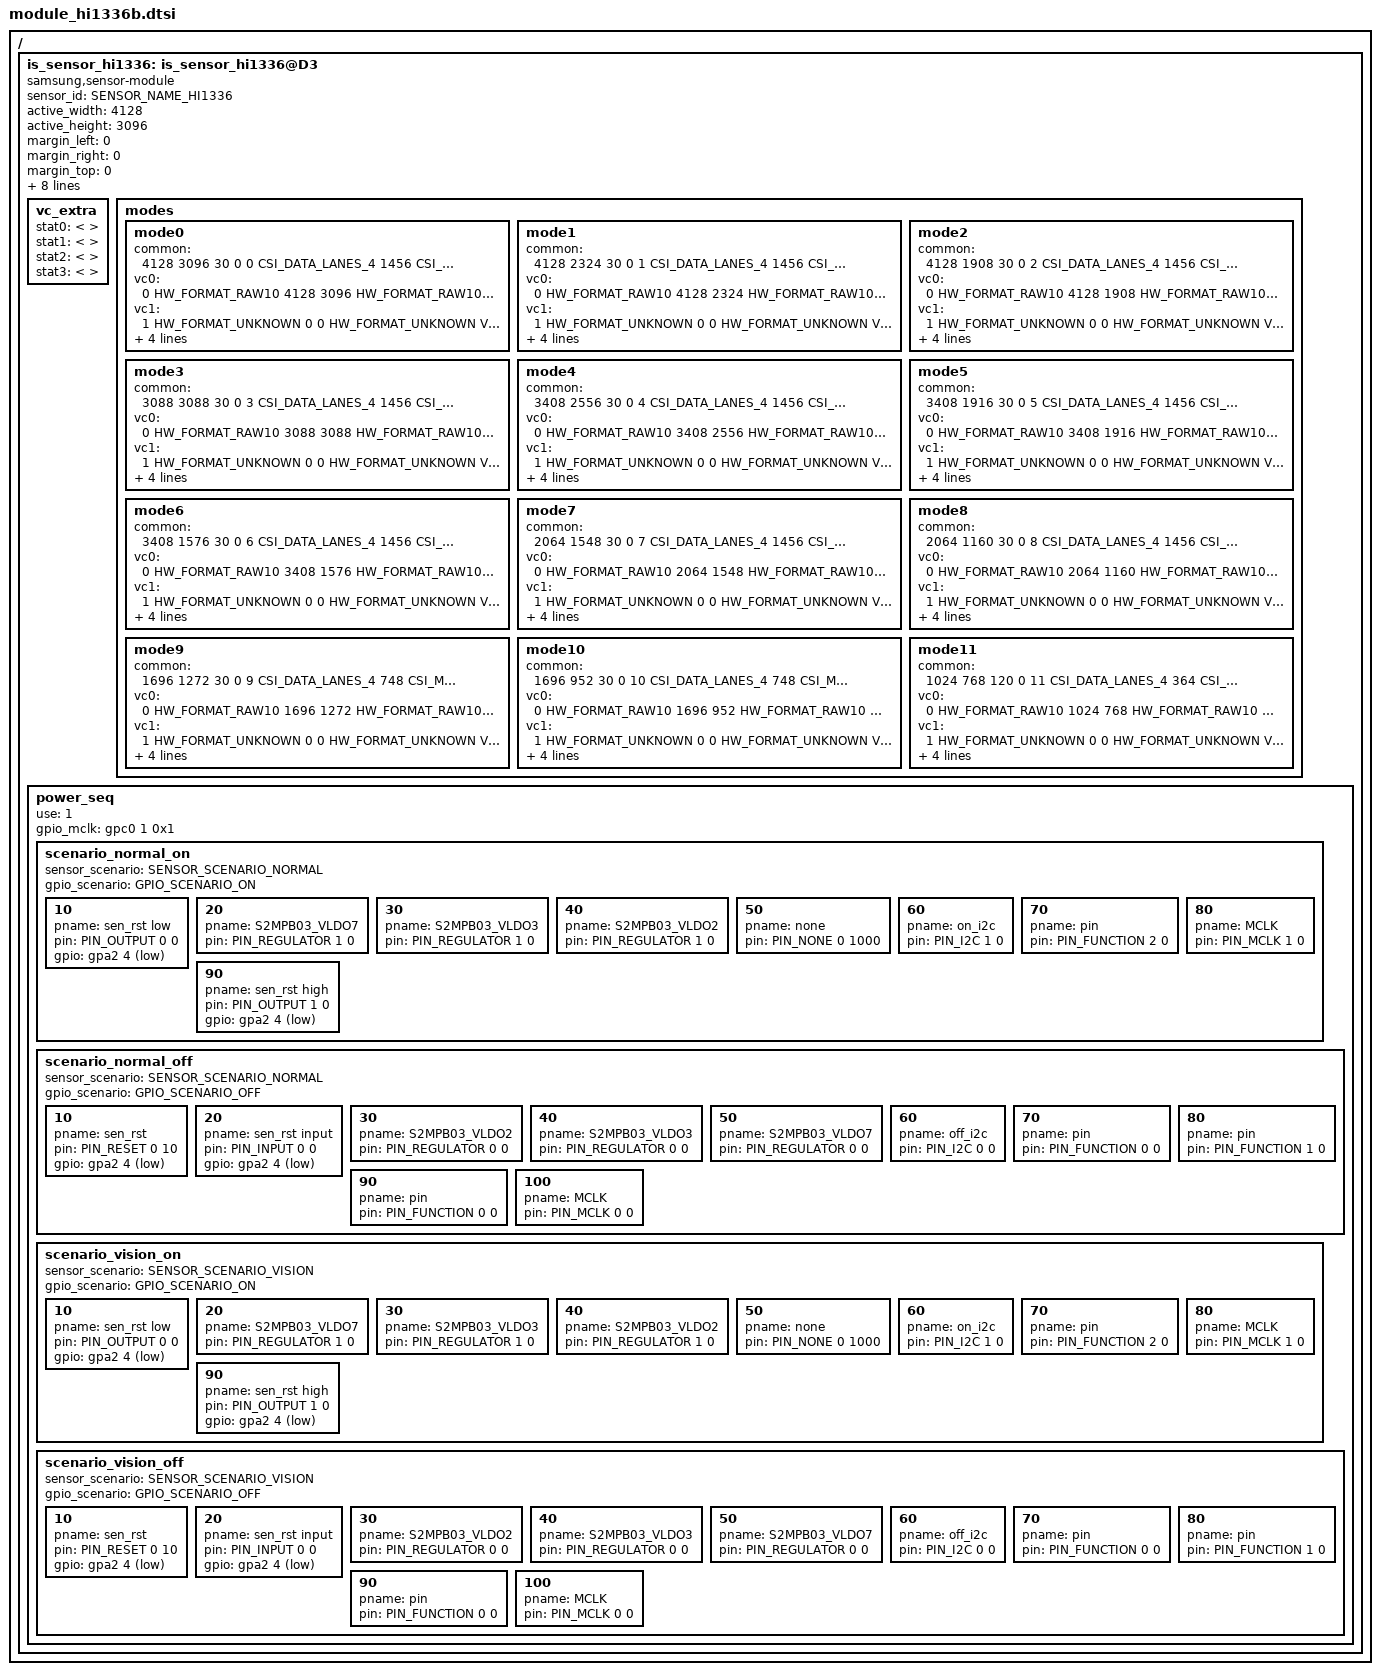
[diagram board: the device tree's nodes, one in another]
/*
 * SAMSUNG EXYNOSxxxx board camera device tree source
 *
 * Copyright (c) 2019 Samsung Electronics Co., Ltd.
 *		http://www.samsung.com
 *
 * This program is free software; you can redistribute it and/or modify
 * it under the terms of the GNU General Public License version 2 as
 * published by the Free Software Foundation.
 */

#include <dt-bindings/camera/exynos_is_dt.h>

/ {
	fragment@camera {
		target-path = "/";
		__overlay__ {
			is_sensor_hi1336: is_sensor_hi1336@D3 {
				compatible = "samsung,sensor-module";

				/* common */
				sensor_id = <SENSOR_NAME_HI1336>;
				active_width = <4128>;
				active_height = <3096>;
				margin_left = <0>;
				margin_right = <0>;
				margin_top = <0>;
				margin_bottom = <0>;
				max_framerate = <120>;
				bitwidth = <10>;
				use_retention_mode = <SENSOR_RETENTION_UNSUPPORTED>;
				sensor_maker = "HYNIX";
				sensor_name = "HI1336";
				setfile_name = "setfile_hi1336.bin";

				status = "okay";

				vc_extra {
					/* ex) statX = <stat_type, sensor_mode, max_width, max_height, max_element> */
					stat0 = </* not avaliable */>;	/* VC_BUF_DATA_TYPE_SENSOR_STAT1 */
					stat1 = </* not avaliable */>;	/* VC_BUF_DATA_TYPE_GENERAL_STAT1 */
					stat2 = </* not avaliable */>;	/* VC_BUF_DATA_TYPE_SENSOR_STAT2 */
					stat3 = </* not avaliable */>;	/* VC_BUF_DATA_TYPE_GENERAL_STAT2 */
				};

				/*
				 * [Mode Information]
				 *
				 *  - Global setting
				 *
				 *
				 *  - Default Mode setting For HI1336B
				 *  [ 0 ] 4128 x 3096(4:3)      @30,  MIPI lane: 4, MIPI data rate(Mbps/lane):  1456, Mclk(Mhz): 26
				 *  [ 1 ] 4128 x 2324(16:9)     @30,  MIPI lane: 4, MIPI data rate(Mbps/lane):  1456, Mclk(Mhz): 26
				 *  [ 2 ] 4128 x 1908(19.5:9)   @30,  MIPI lane: 4, MIPI data rate(Mbps/lane):  1456, Mclk(Mhz): 26
				 *  [ 3 ] 3088 x 3088(1:1)      @30,  MIPI lane: 4, MIPI data rate(Mbps/lane):  1456, Mclk(Mhz): 26
				 *      - Sensor Crop Mode (68') setting For HI1336B
				 *  [ 4 ] 3408 x 2556(4:3)      @30,  MIPI lane: 4, MIPI data rate(Mbps/lane):  1456, Mclk(Mhz): 26
				 *  [ 5 ] 3408 x 1916(16:9)     @30,  MIPI lane: 4, MIPI data rate(Mbps/lane):  1456, Mclk(Mhz): 26
				 *  [ 6 ] 3408 x 1576(19.5:9)   @30,  MIPI lane: 4, MIPI data rate(Mbps/lane):  1456, Mclk(Mhz): 26
				 *  [ 7 ] 2064 x 1548(4:3)      @30,  MIPI lane: 4, MIPI data rate(Mbps/lane):  1456, Mclk(Mhz): 26
				 *  [ 8 ] 2064 x 1160(16:9)     @30,  MIPI lane: 4, MIPI data rate(Mbps/lane):  1456, Mclk(Mhz): 26
				 *  [ 9 ] 1696 x 1272(4:3)      @30,  MIPI lane: 4, MIPI data rate(Mbps/lane):  747.5, Mclk(Mhz): 26
				 *  [ 10 ] 1696 x 952 (16:9)     @30,  MIPI lane: 4, MIPI data rate(Mbps/lane):  747.5, Mclk(Mhz): 26
				 *       - FAST AE (4 binning) setting For HI1336B
				 *  [ 11 ] 1024 x 768(4:3)       @120, MIPI lane: 4, MIPI data rate(Mbps/lane):   364, Mclk(Mhz): 26
				 *
				 *
				 *  - Fsync setting
				 *  [ 0 ] Normal
				 *  [ 1 ] Slave
				 *  [ 2 ] Master full
				 *  [ 3 ] Master 2-binnig
				 *  [ 4 ] Master 4-binning
				 *
				 */

				/* sensor modes */
				modes {
						/* common = <width, height, fps, settle, mode, lane, speed, interleave, lrte, pd_mode> */
						/* vcX = <map, hwformat, width, height, hwformat, type, width, height> */
					/* Full Crop(4128x3096) 4:3 */
					mode0 {
						common = <4128 3096 30 0 0 CSI_DATA_LANES_4 1456 CSI_MODE_CH0_ONLY LRTE_DISABLE PD_NONE EX_NONE>;
						vc0 = </* in */ 0 HW_FORMAT_RAW10 4128 3096	/* out */ HW_FORMAT_RAW10 VC_NOTHING 0 0>;
						vc1 = </* in */ 1 HW_FORMAT_UNKNOWN 0 0		/* out */ HW_FORMAT_UNKNOWN VC_NOTHING 0 0>;
						vc2 = </* in */ 2 HW_FORMAT_UNKNOWN 0 0		/* out */ HW_FORMAT_UNKNOWN VC_NOTHING 0 0>;
						vc3 = </* in */ 3 HW_FORMAT_UNKNOWN 0 0		/* out */ HW_FORMAT_UNKNOWN VC_NOTHING 0 0>;
					};

					/* Full Crop(4128x2324) 16:9 */
					mode1 {
						common = <4128 2324 30 0 1 CSI_DATA_LANES_4 1456 CSI_MODE_CH0_ONLY LRTE_DISABLE PD_NONE EX_NONE>;
						vc0 = <0 HW_FORMAT_RAW10 4128 2324	/* out */ HW_FORMAT_RAW10 VC_NOTHING 0 0>;
						vc1 = <1 HW_FORMAT_UNKNOWN 0 0		/* out */ HW_FORMAT_UNKNOWN VC_NOTHING 0 0>;
						vc2 = <2 HW_FORMAT_UNKNOWN 0 0		/* out */ HW_FORMAT_UNKNOWN VC_NOTHING 0 0>;
						vc3 = <3 HW_FORMAT_UNKNOWN 0 0		/* out */ HW_FORMAT_UNKNOWN VC_NOTHING 0 0>;
					};

					/* Full Crop(4128x1908) 19.5:9 */
					mode2 {
						common = <4128 1908 30 0 2 CSI_DATA_LANES_4 1456 CSI_MODE_CH0_ONLY LRTE_DISABLE PD_NONE EX_NONE>;
						vc0 = <0 HW_FORMAT_RAW10 4128 1908	/* out */ HW_FORMAT_RAW10 VC_NOTHING 0 0>;
						vc1 = <1 HW_FORMAT_UNKNOWN 0 0		/* out */ HW_FORMAT_UNKNOWN VC_NOTHING 0 0>;
						vc2 = <2 HW_FORMAT_UNKNOWN 0 0		/* out */ HW_FORMAT_UNKNOWN VC_NOTHING 0 0>;
						vc3 = <3 HW_FORMAT_UNKNOWN 0 0		/* out */ HW_FORMAT_UNKNOWN VC_NOTHING 0 0>;
					};

					/* Full Crop(3088x3088) 1:1 */
					mode3 {
						common = <3088 3088 30 0 3 CSI_DATA_LANES_4 1456 CSI_MODE_CH0_ONLY LRTE_DISABLE PD_NONE EX_NONE>;
						vc0 = <0 HW_FORMAT_RAW10 3088 3088	/* out */ HW_FORMAT_RAW10 VC_NOTHING 0 0>;
						vc1 = <1 HW_FORMAT_UNKNOWN 0 0		/* out */ HW_FORMAT_UNKNOWN VC_NOTHING 0 0>;
						vc2 = <2 HW_FORMAT_UNKNOWN 0 0		/* out */ HW_FORMAT_UNKNOWN VC_NOTHING 0 0>;
						vc3 = <3 HW_FORMAT_UNKNOWN 0 0		/* out */ HW_FORMAT_UNKNOWN VC_NOTHING 0 0>;
					};

					/* Full Crop(3408x2556) 4:3 */
					mode4 {
						common = <3408 2556 30 0 4 CSI_DATA_LANES_4 1456 CSI_MODE_CH0_ONLY LRTE_DISABLE PD_NONE EX_NONE>;
						vc0 = <0 HW_FORMAT_RAW10 3408 2556	/* out */ HW_FORMAT_RAW10 VC_NOTHING 0 0>;
						vc1 = <1 HW_FORMAT_UNKNOWN 0 0		/* out */ HW_FORMAT_UNKNOWN VC_NOTHING 0 0>;
						vc2 = <2 HW_FORMAT_UNKNOWN 0 0		/* out */ HW_FORMAT_UNKNOWN VC_NOTHING 0 0>;
						vc3 = <3 HW_FORMAT_UNKNOWN 0 0		/* out */ HW_FORMAT_UNKNOWN VC_NOTHING 0 0>;
					};

					/* Full Crop(3408x1916) 16:9 */
					mode5 {
						common = <3408 1916 30 0 5 CSI_DATA_LANES_4 1456 CSI_MODE_CH0_ONLY LRTE_DISABLE PD_NONE EX_NONE>;
						vc0 = <0 HW_FORMAT_RAW10 3408 1916	/* out */ HW_FORMAT_RAW10 VC_NOTHING 0 0>;
						vc1 = <1 HW_FORMAT_UNKNOWN 0 0		/* out */ HW_FORMAT_UNKNOWN VC_NOTHING 0 0>;
						vc2 = <2 HW_FORMAT_UNKNOWN 0 0		/* out */ HW_FORMAT_UNKNOWN VC_NOTHING 0 0>;
						vc3 = <3 HW_FORMAT_UNKNOWN 0 0		/* out */ HW_FORMAT_UNKNOWN VC_NOTHING 0 0>;
					};

					/* Full Crop(3408x1576) 19.5:9 */
					mode6 {
						common = <3408 1576 30 0 6 CSI_DATA_LANES_4 1456 CSI_MODE_CH0_ONLY LRTE_DISABLE PD_NONE EX_NONE>;
						vc0 = <0 HW_FORMAT_RAW10 3408 1576	/* out */ HW_FORMAT_RAW10 VC_NOTHING 0 0>;
						vc1 = <1 HW_FORMAT_UNKNOWN 0 0		/* out */ HW_FORMAT_UNKNOWN VC_NOTHING 0 0>;
						vc2 = <2 HW_FORMAT_UNKNOWN 0 0		/* out */ HW_FORMAT_UNKNOWN VC_NOTHING 0 0>;
						vc3 = <3 HW_FORMAT_UNKNOWN 0 0		/* out */ HW_FORMAT_UNKNOWN VC_NOTHING 0 0>;
					};

					/* Full Crop(2064x1548) 4:3 */
					mode7 {
						common = <2064 1548 30 0 7 CSI_DATA_LANES_4 1456 CSI_MODE_CH0_ONLY LRTE_DISABLE PD_NONE EX_NONE>;
						vc0 = <0 HW_FORMAT_RAW10 2064 1548	/* out */ HW_FORMAT_RAW10 VC_NOTHING 0 0>;
						vc1 = <1 HW_FORMAT_UNKNOWN 0 0		/* out */ HW_FORMAT_UNKNOWN VC_NOTHING 0 0>;
						vc2 = <2 HW_FORMAT_UNKNOWN 0 0		/* out */ HW_FORMAT_UNKNOWN VC_NOTHING 0 0>;
						vc3 = <3 HW_FORMAT_UNKNOWN 0 0		/* out */ HW_FORMAT_UNKNOWN VC_NOTHING 0 0>;
					};

					/* Full Crop(2064x1160) 16:9 */
					mode8 {
						common = <2064 1160 30 0 8 CSI_DATA_LANES_4 1456 CSI_MODE_CH0_ONLY LRTE_DISABLE PD_NONE EX_NONE>;
						vc0 = <0 HW_FORMAT_RAW10 2064 1160	/* out */ HW_FORMAT_RAW10 VC_NOTHING 0 0>;
						vc1 = <1 HW_FORMAT_UNKNOWN 0 0		/* out */ HW_FORMAT_UNKNOWN VC_NOTHING 0 0>;
						vc2 = <2 HW_FORMAT_UNKNOWN 0 0		/* out */ HW_FORMAT_UNKNOWN VC_NOTHING 0 0>;
						vc3 = <3 HW_FORMAT_UNKNOWN 0 0		/* out */ HW_FORMAT_UNKNOWN VC_NOTHING 0 0>;
					};

					/* Full Crop(1696x1272) 19.5:9 */
					mode9 {
						common = <1696 1272 30 0 9 CSI_DATA_LANES_4 748 CSI_MODE_CH0_ONLY LRTE_DISABLE PD_NONE EX_NONE>;
						vc0 = <0 HW_FORMAT_RAW10 1696 1272	/* out */ HW_FORMAT_RAW10 VC_NOTHING 0 0>;
						vc1 = <1 HW_FORMAT_UNKNOWN 0 0		/* out */ HW_FORMAT_UNKNOWN VC_NOTHING 0 0>;
						vc2 = <2 HW_FORMAT_UNKNOWN 0 0		/* out */ HW_FORMAT_UNKNOWN VC_NOTHING 0 0>;
						vc3 = <3 HW_FORMAT_UNKNOWN 0 0		/* out */ HW_FORMAT_UNKNOWN VC_NOTHING 0 0>;
					};

					/* Full Crop(1696x952) 1:1 */
					mode10 {
						common = <1696 952 30 0 10 CSI_DATA_LANES_4 748 CSI_MODE_CH0_ONLY LRTE_DISABLE PD_NONE EX_NONE>;
						vc0 = <0 HW_FORMAT_RAW10 1696 952	/* out */ HW_FORMAT_RAW10 VC_NOTHING 0 0>;
						vc1 = <1 HW_FORMAT_UNKNOWN 0 0		/* out */ HW_FORMAT_UNKNOWN VC_NOTHING 0 0>;
						vc2 = <2 HW_FORMAT_UNKNOWN 0 0		/* out */ HW_FORMAT_UNKNOWN VC_NOTHING 0 0>;
						vc3 = <3 HW_FORMAT_UNKNOWN 0 0		/* out */ HW_FORMAT_UNKNOWN VC_NOTHING 0 0>;
					};

					/* 4-binning FastAE */
					mode11 {
						common = <1024 768 120 0 11 CSI_DATA_LANES_4 364 CSI_MODE_CH0_ONLY LRTE_DISABLE PD_NONE EX_NONE>;
						vc0 = <0 HW_FORMAT_RAW10 1024 768	/* out */ HW_FORMAT_RAW10 VC_NOTHING 0 0>;
						vc1 = <1 HW_FORMAT_UNKNOWN 0 0		/* out */ HW_FORMAT_UNKNOWN VC_NOTHING 0 0>;
						vc2 = <2 HW_FORMAT_UNKNOWN 0 0		/* out */ HW_FORMAT_UNKNOWN VC_NOTHING 0 0>;
						vc3 = <3 HW_FORMAT_UNKNOWN 0 0		/* out */ HW_FORMAT_UNKNOWN VC_NOTHING 0 0>;
					};
				};

				power_seq {
					use = <1>;
					gpio_mclk = <&gpc0 1 0x1>;

					scenario_normal_on {
						sensor_scenario = <SENSOR_SCENARIO_NORMAL>;
						gpio_scenario = <GPIO_SCENARIO_ON>;

						/* A start node number should be over the 10 for reserved number 0~9. */
						/* pname = "name"; pin = <act value dealy voltage>; gpio = <gpx# # 0x1>; */
						10 { pname = "sen_rst low"; pin = <PIN_OUTPUT 0 0>; gpio = <&gpa2 4 0x1>; };
						20 { pname = "S2MPB03_VLDO7"; pin = <PIN_REGULATOR 1 0>; };
						30 { pname = "S2MPB03_VLDO3"; pin = <PIN_REGULATOR 1 0>; };
						40 { pname = "S2MPB03_VLDO2"; pin = <PIN_REGULATOR 1 0>; };
						50 { pname = "none"; pin = <PIN_NONE 0 1000>; };
						60 { pname = "on_i2c"; pin = <PIN_I2C 1 0>; };
						70 { pname = "pin"; pin = <PIN_FUNCTION 2 0>; };
						80 { pname = "MCLK"; pin = <PIN_MCLK 1 0>; };
						90 { pname = "sen_rst high"; pin = <PIN_OUTPUT 1 0>; gpio = <&gpa2 4 0x1>; };
					};

					scenario_normal_off {
						sensor_scenario = <SENSOR_SCENARIO_NORMAL>;
						gpio_scenario = <GPIO_SCENARIO_OFF>;

						/* A start node number should be over the 10 for reserved number 0~9. */
						/* pname = "name"; pin = <act value dealy voltage>; gpio = <gpx# # 0x1>; */
						10 { pname = "sen_rst"; pin = <PIN_RESET 0 10>; gpio = <&gpa2 4 0x1>; };
						20 { pname = "sen_rst input"; pin = <PIN_INPUT 0 0>; gpio = <&gpa2 4 0x1>; };
						30 { pname = "S2MPB03_VLDO2"; pin = <PIN_REGULATOR 0 0>; };
						40 { pname = "S2MPB03_VLDO3"; pin = <PIN_REGULATOR 0 0>; };
						50 { pname = "S2MPB03_VLDO7"; pin = <PIN_REGULATOR 0 0>; };
						60 { pname = "off_i2c"; pin = <PIN_I2C 0 0>; };
						70 { pname = "pin"; pin = <PIN_FUNCTION 0 0>; };
						80 { pname = "pin"; pin = <PIN_FUNCTION 1 0>; };
						90 { pname = "pin"; pin = <PIN_FUNCTION 0 0>; };
						100 { pname = "MCLK"; pin = <PIN_MCLK 0 0>; };
					};

					scenario_vision_on {
						sensor_scenario = <SENSOR_SCENARIO_VISION>;
						gpio_scenario = <GPIO_SCENARIO_ON>;

						/* A start node number should be over the 10 for reserved number 0~9. */
						/* pname = "name"; pin = <act value dealy voltage>; gpio = <gpx# # 0x1>; */
						10 { pname = "sen_rst low"; pin = <PIN_OUTPUT 0 0>; gpio = <&gpa2 4 0x1>; };
						20 { pname = "S2MPB03_VLDO7"; pin = <PIN_REGULATOR 1 0>; };
						30 { pname = "S2MPB03_VLDO3"; pin = <PIN_REGULATOR 1 0>; };
						40 { pname = "S2MPB03_VLDO2"; pin = <PIN_REGULATOR 1 0>; };
						50 { pname = "none"; pin = <PIN_NONE 0 1000>; };
						60 { pname = "on_i2c"; pin = <PIN_I2C 1 0>; };
						70 { pname = "pin"; pin = <PIN_FUNCTION 2 0>; };
						80 { pname = "MCLK"; pin = <PIN_MCLK 1 0>; };
						90 { pname = "sen_rst high"; pin = <PIN_OUTPUT 1 0>; gpio = <&gpa2 4 0x1>; };
					};

					scenario_vision_off {
						sensor_scenario = <SENSOR_SCENARIO_VISION>;
						gpio_scenario = <GPIO_SCENARIO_OFF>;

						/* A start node number should be over the 10 for reserved number 0~9. */
						/* pname = "name"; pin = <act value dealy voltage>; gpio = <gpx# # 0x1>; */
						10 { pname = "sen_rst"; pin = <PIN_RESET 0 10>; gpio = <&gpa2 4 0x1>; };
						20 { pname = "sen_rst input"; pin = <PIN_INPUT 0 0>; gpio = <&gpa2 4 0x1>; };
						30 { pname = "S2MPB03_VLDO2"; pin = <PIN_REGULATOR 0 0>; };
						40 { pname = "S2MPB03_VLDO3"; pin = <PIN_REGULATOR 0 0>; };
						50 { pname = "S2MPB03_VLDO7"; pin = <PIN_REGULATOR 0 0>; };
						60 { pname = "off_i2c"; pin = <PIN_I2C 0 0>; };
						70 { pname = "pin"; pin = <PIN_FUNCTION 0 0>; };
						80 { pname = "pin"; pin = <PIN_FUNCTION 1 0>; };
						90 { pname = "pin"; pin = <PIN_FUNCTION 0 0>; };
						100 { pname = "MCLK"; pin = <PIN_MCLK 0 0>; };
					};
				};
			};
		}; /* end of __overlay__ */
	}; /* end of fragment */
}; /* end of root */
